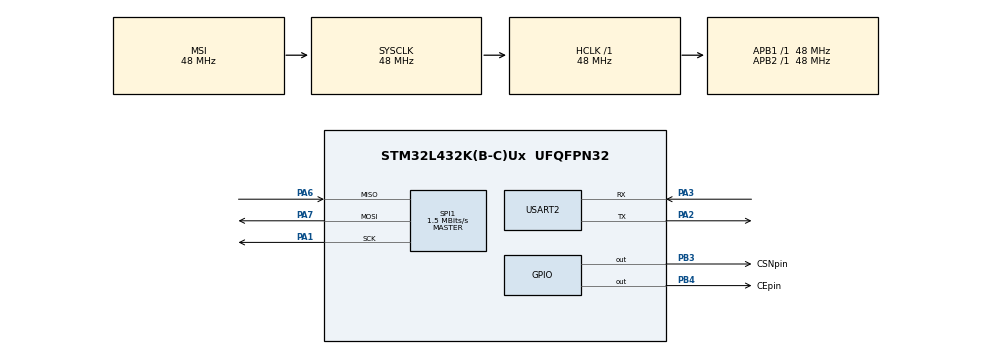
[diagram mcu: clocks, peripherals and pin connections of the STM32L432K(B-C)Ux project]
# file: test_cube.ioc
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Mcu.Family=STM32L4
Mcu.Name=STM32L432K(B-C)Ux
Mcu.Package=UFQFPN32
NVIC.PriorityGroup=NVIC_PRIORITYGROUP_4
PA1.Mode=Full_Duplex_Master
PA1.Signal=SPI1_SCK
PA2.Mode=Asynchronous
PA2.Signal=USART2_TX
PA3.Mode=Asynchronous
PA3.Signal=USART2_RX
PA6.Mode=Full_Duplex_Master
PA6.Signal=SPI1_MISO
PA7.Mode=Full_Duplex_Master
PA7.Signal=SPI1_MOSI
PB3\ (JTDO-TRACESWO).GPIO_Label=CSNpin
PB3\ (JTDO-TRACESWO).Signal=GPIO_Output
PB4\ (NJTRST).GPIO_Label=CEpin
PB4\ (NJTRST).Signal=GPIO_Output
ProjectManager.HeapSize=0x200
ProjectManager.StackSize=0x400
ProjectManager.TargetToolchain=STM32CubeIDE
RCC.ADCFreq_Value=192000000
RCC.AHBFreq_Value=48000000
RCC.APB1Freq_Value=48000000
RCC.APB1TimFreq_Value=48000000
RCC.APB2Freq_Value=48000000
RCC.APB2TimFreq_Value=48000000
RCC.CortexFreq_Value=48000000
RCC.HCLKFreq_Value=48000000
RCC.HSE_VALUE=8000000
RCC.HSI48_VALUE=48000000
RCC.HSI_VALUE=16000000
RCC.LSE_VALUE=32768
RCC.MSIClockRange=RCC_MSIRANGE_11
RCC.MSI_VALUE=48000000
RCC.SYSCLKFreq_VALUE=48000000
RCC.USBFreq_Value=192000000
RCC.VCOOutputFreq_Value=384000000
SPI1.BaudRatePrescaler=SPI_BAUDRATEPRESCALER_32
SPI1.CalculateBaudRate=1.5 MBits/s
SPI1.DataSize=SPI_DATASIZE_8BIT
SPI1.Direction=SPI_DIRECTION_2LINES
SPI1.Mode=SPI_MODE_MASTER
SPI1.VirtualType=VM_MASTER
USART2.VirtualMode-Asynchronous=VM_ASYNC
board=custom

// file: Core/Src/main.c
/* USER CODE BEGIN Header */
/**
  ******************************************************************************
  * @file           : main.c
  * @brief          : Main program body
  ******************************************************************************
  * @attention
  *
  * Copyright (c) 2023 STMicroelectronics.
  * All rights reserved.
  *
  * This software is licensed under terms that can be found in the LICENSE file
  * in the root directory of this software component.
  * If no LICENSE file comes with this software, it is provided AS-IS.
  *
  ******************************************************************************
  */
/* USER CODE END Header */
#include "main.h"

/* USER CODE BEGIN Includes */
#include "MY_NRF24.h"

/* USER CODE END Includes */

SPI_HandleTypeDef hspi1;

UART_HandleTypeDef huart2;

void SystemClock_Config(void);
static void MX_GPIO_Init(void);
static void MX_SPI1_Init(void);
static void MX_USART2_UART_Init(void);

int main(void)
{

  /* MCU Configuration--------------------------------------------------------*/

  /* Reset of all peripherals, Initializes the Flash interface and the Systick. */
  HAL_Init();

  /* Configure the system clock */
  SystemClock_Config();

  /* Initialize all configured peripherals */
  MX_GPIO_Init();
  MX_SPI1_Init();
  MX_USART2_UART_Init();
  /* USER CODE BEGIN 2 */
  //CSNpin_Pin|CEpin_Pin

  //NRF24_begin(GPIOB, CSNpin_Pin, CEpin_Pin, hspi1);
  /*
  nrf24_DebugUART_Init(huart2);
  printRadioSettings();
  */
  uint8_t readData;

  readData = NRF24_read_register(REG_RX_ADDR_P5);
  NRF24_write_register(REG_RX_ADDR_P5, 0xDE);
  readData = NRF24_read_register(REG_CONFIG);
  NRF24_write_register(REG_RX_ADDR_P5, 0xAD);
  readData = NRF24_read_register(REG_RX_ADDR_P5);

  /* USER CODE END 2 */

  /* Infinite loop */
  while (1)
  {

  }
}

void SystemClock_Config(void)
{
  RCC_OscInitTypeDef RCC_OscInitStruct = {0};
  RCC_ClkInitTypeDef RCC_ClkInitStruct = {0};

  /** Configure the main internal regulator output voltage
  */
  if (HAL_PWREx_ControlVoltageScaling(PWR_REGULATOR_VOLTAGE_SCALE1) != HAL_OK)
  {
    Error_Handler();
  }

  /** Initializes the RCC Oscillators according to the specified parameters
  * in the RCC_OscInitTypeDef structure.
  */
  RCC_OscInitStruct.OscillatorType = RCC_OSCILLATORTYPE_MSI;
  RCC_OscInitStruct.MSIState = RCC_MSI_ON;
  RCC_OscInitStruct.MSICalibrationValue = 0;
  RCC_OscInitStruct.MSIClockRange = RCC_MSIRANGE_11;
  RCC_OscInitStruct.PLL.PLLState = RCC_PLL_NONE;
  if (HAL_RCC_OscConfig(&RCC_OscInitStruct) != HAL_OK)
  {
    Error_Handler();
  }

  /** Initializes the CPU, AHB and APB buses clocks
  */
  RCC_ClkInitStruct.ClockType = RCC_CLOCKTYPE_HCLK|RCC_CLOCKTYPE_SYSCLK
                              |RCC_CLOCKTYPE_PCLK1|RCC_CLOCKTYPE_PCLK2;
  RCC_ClkInitStruct.SYSCLKSource = RCC_SYSCLKSOURCE_MSI;
  RCC_ClkInitStruct.AHBCLKDivider = RCC_SYSCLK_DIV1;
  RCC_ClkInitStruct.APB1CLKDivider = RCC_HCLK_DIV1;
  RCC_ClkInitStruct.APB2CLKDivider = RCC_HCLK_DIV1;

  if (HAL_RCC_ClockConfig(&RCC_ClkInitStruct, FLASH_LATENCY_2) != HAL_OK)
  {
    Error_Handler();
  }
}

static void MX_SPI1_Init(void)
{

  /* SPI1 parameter configuration*/
  hspi1.Instance = SPI1;
  hspi1.Init.Mode = SPI_MODE_MASTER;
  hspi1.Init.Direction = SPI_DIRECTION_2LINES;
  hspi1.Init.DataSize = SPI_DATASIZE_8BIT;
  hspi1.Init.CLKPolarity = SPI_POLARITY_LOW;
  hspi1.Init.CLKPhase = SPI_PHASE_1EDGE;
  hspi1.Init.NSS = SPI_NSS_SOFT;
  hspi1.Init.BaudRatePrescaler = SPI_BAUDRATEPRESCALER_32;
  hspi1.Init.FirstBit = SPI_FIRSTBIT_MSB;
  hspi1.Init.TIMode = SPI_TIMODE_DISABLE;
  hspi1.Init.CRCCalculation = SPI_CRCCALCULATION_DISABLE;
  hspi1.Init.CRCPolynomial = 7;
  hspi1.Init.CRCLength = SPI_CRC_LENGTH_DATASIZE;
  hspi1.Init.NSSPMode = SPI_NSS_PULSE_ENABLE;
  if (HAL_SPI_Init(&hspi1) != HAL_OK)
  {
    Error_Handler();
  }

}

static void MX_USART2_UART_Init(void)
{

  huart2.Instance = USART2;
  huart2.Init.BaudRate = 115200;
  huart2.Init.WordLength = UART_WORDLENGTH_8B;
  huart2.Init.StopBits = UART_STOPBITS_1;
  huart2.Init.Parity = UART_PARITY_NONE;
  huart2.Init.Mode = UART_MODE_TX_RX;
  huart2.Init.HwFlowCtl = UART_HWCONTROL_NONE;
  huart2.Init.OverSampling = UART_OVERSAMPLING_16;
  huart2.Init.OneBitSampling = UART_ONE_BIT_SAMPLE_DISABLE;
  huart2.AdvancedInit.AdvFeatureInit = UART_ADVFEATURE_NO_INIT;
  if (HAL_UART_Init(&huart2) != HAL_OK)
  {
    Error_Handler();
  }

}

static void MX_GPIO_Init(void)
{
  GPIO_InitTypeDef GPIO_InitStruct = {0};

  /* GPIO Ports Clock Enable */
  __HAL_RCC_GPIOA_CLK_ENABLE();
  __HAL_RCC_GPIOB_CLK_ENABLE();

  /*Configure GPIO pin Output Level */
  HAL_GPIO_WritePin(GPIOB, CSNpin_Pin|CEpin_Pin, GPIO_PIN_RESET);

  /*Configure GPIO pins : CSNpin_Pin CEpin_Pin */
  GPIO_InitStruct.Pin = CSNpin_Pin|CEpin_Pin;
  GPIO_InitStruct.Mode = GPIO_MODE_OUTPUT_PP;
  GPIO_InitStruct.Pull = GPIO_NOPULL;
  GPIO_InitStruct.Speed = GPIO_SPEED_FREQ_LOW;
  HAL_GPIO_Init(GPIOB, &GPIO_InitStruct);

}

void Error_Handler(void)
{
  __disable_irq();
  while (1)
  {
  }
}
